CM_ "AUTOGENERATED FILE, DO NOT EDIT";

CM_ "fca_fastback_limited_edition_2024.dbc starts here";
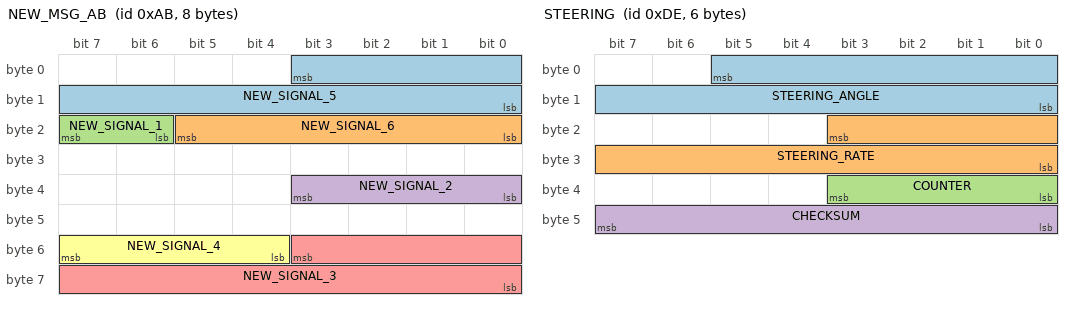
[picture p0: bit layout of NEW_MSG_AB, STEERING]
BO_ 171 NEW_MSG_AB: 8 XXX
 SG_ NEW_SIGNAL_5 : 3|12@0+ (1,0) [0|4095] "" XXX
 SG_ NEW_SIGNAL_6 : 21|6@0+ (1,0) [0|63] "" XXX
 SG_ NEW_SIGNAL_1 : 23|2@0+ (1,0) [0|3] "" XXX
 SG_ NEW_SIGNAL_2 : 35|4@0+ (1,0) [0|15] "" XXX
 SG_ NEW_SIGNAL_3 : 51|12@0+ (1,0) [0|4095] "" XXX
 SG_ NEW_SIGNAL_4 : 55|4@0+ (1,0) [0|15] "" XXX

BO_ 222 STEERING: 6 EPS
 SG_ STEERING_ANGLE : 5|14@0+ (0.1,-718.7) [0|16383] "deg" XXX
 SG_ STEERING_RATE : 19|12@0+ (0.5,-1000) [0|4095] "deg/s" XXX
 SG_ COUNTER : 35|4@0+ (1,0) [0|15] "" XXX
 SG_ CHECKSUM : 47|8@0+ (1,0) [0|255] "" XXX

BO_ 228 NEW_MSG_E4: 6 XXX
 SG_ NEW_SIGNAL_1 : 13|1@0+ (1,0) [0|1] "" XXX

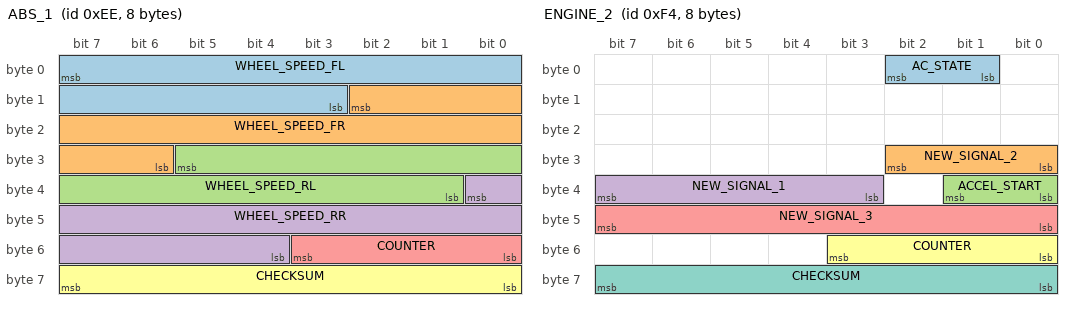
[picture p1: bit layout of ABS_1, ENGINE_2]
BO_ 238 ABS_1: 8 ABS
 SG_ WHEEL_SPEED_FL : 7|13@0+ (0.017,0) [0|8191] "m/s" XXX
 SG_ WHEEL_SPEED_FR : 10|13@0+ (0.017,0) [0|8191] "m/s" XXX
 SG_ WHEEL_SPEED_RL : 29|13@0+ (0.017,0) [0|8191] "m/s" XXX
 SG_ WHEEL_SPEED_RR : 32|13@0+ (0.017,0) [0|8191] "m/s" XXX
 SG_ COUNTER : 51|4@0+ (1,0) [0|15] "" XXX
 SG_ CHECKSUM : 63|8@0+ (1,0) [0|255] "" XXX

BO_ 241 NEW_MSG_F1: 8 XXX
 SG_ COUNTER : 51|4@0+ (1,0) [0|15] "" XXX
 SG_ CHECKSUM : 63|8@0+ (1,0) [0|255] "" XXX

BO_ 244 ENGINE_2: 8 XXX
 SG_ AC_STATE : 1|2@1+ (1,0) [0|7] "" XXX
 SG_ NEW_SIGNAL_2 : 24|3@1+ (1,0) [0|7] "" XXX
 SG_ ACCEL_START : 32|2@1+ (1,0) [0|3] "" XXX
 SG_ NEW_SIGNAL_1 : 35|5@1+ (1,0) [0|31] "" XXX
 SG_ NEW_SIGNAL_3 : 40|8@1+ (1,0) [0|255] "" XXX
 SG_ COUNTER : 51|4@0+ (1,0) [0|15] "" XXX
 SG_ CHECKSUM : 63|8@0+ (1,0) [0|255] "" XXX

BO_ 249 NEW_MSG_F9: 4 XXX
 SG_ COUNTER : 19|4@0+ (1,0) [0|15] "" XXX
 SG_ CHECKSUM : 31|8@0+ (1,0) [0|255] "" XXX

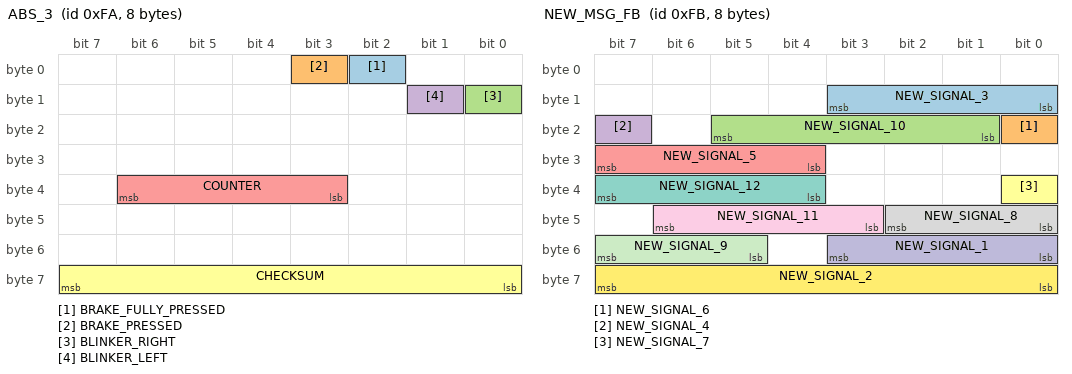
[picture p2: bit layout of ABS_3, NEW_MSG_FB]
BO_ 250 ABS_3: 8 ABS
 SG_ BRAKE_FULLY_PRESSED : 2|1@0+ (1,0) [0|1] "" XXX
 SG_ BRAKE_PRESSED : 3|1@0+ (1,0) [0|1] "" XXX
 SG_ BLINKER_RIGHT : 8|1@0+ (1,0) [0|1] "" XXX
 SG_ BLINKER_LEFT : 9|1@0+ (1,0) [0|1] "" XXX
 SG_ COUNTER : 38|4@0+ (1,0) [0|15] "" XXX
 SG_ CHECKSUM : 63|8@0+ (1,0) [0|255] "" XXX

BO_ 251 NEW_MSG_FB: 8 XXX
 SG_ NEW_SIGNAL_3 : 8|4@1+ (1,0) [0|15] "" XXX
 SG_ NEW_SIGNAL_6 : 16|1@0+ (1,0) [0|1] "" XXX
 SG_ NEW_SIGNAL_10 : 17|5@1+ (1,0) [0|31] "" XXX
 SG_ NEW_SIGNAL_4 : 23|1@0+ (1,0) [0|1] "" XXX
 SG_ NEW_SIGNAL_5 : 28|4@1+ (1,0) [0|15] "" XXX
 SG_ NEW_SIGNAL_7 : 32|1@0+ (1,0) [0|1] "" XXX
 SG_ NEW_SIGNAL_12 : 36|4@1+ (1,0) [0|15] "" XXX
 SG_ NEW_SIGNAL_8 : 40|3@1+ (1,0) [0|7] "" XXX
 SG_ NEW_SIGNAL_11 : 43|4@1+ (1,0) [0|15] "" XXX
 SG_ NEW_SIGNAL_1 : 48|4@1+ (1,0) [0|15] "" XXX
 SG_ NEW_SIGNAL_9 : 53|3@1+ (1,0) [0|7] "" XXX
 SG_ NEW_SIGNAL_2 : 56|8@1+ (1,0) [0|255] "" XXX

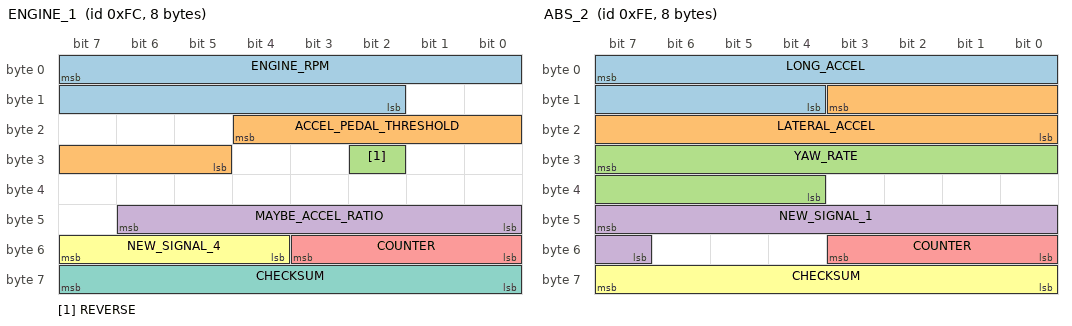
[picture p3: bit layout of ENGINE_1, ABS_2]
BO_ 252 ENGINE_1: 8 ENGINE
 SG_ ENGINE_RPM : 7|14@0+ (1,30) [0|255] "rev/min" XXX
 SG_ ACCEL_PEDAL_THRESHOLD : 20|8@0+ (0.3942,0) [0|255] "percent" XXX
 SG_ REVERSE : 26|1@0+ (1,0) [0|1] "" XXX
 SG_ MAYBE_ACCEL_RATIO : 40|7@1+ (1,0) [0|127] "" XXX
 SG_ COUNTER : 51|4@0+ (1,0) [0|15] "" XXX
 SG_ NEW_SIGNAL_4 : 52|4@1+ (1,0) [0|15] "" XXX
 SG_ CHECKSUM : 63|8@0+ (1,0) [0|255] "" XXX

BO_ 254 ABS_2: 8 ABS
 SG_ LONG_ACCEL : 7|12@0+ (0.01,-20.48) [0|4095] "m/s2" XXX
 SG_ LATERAL_ACCEL : 11|12@0+ (0.01,-20.48) [0|4095] "m/s2" XXX
 SG_ YAW_RATE : 31|12@0+ (-0.0014,2.86) [0|4095] "rad/s" XXX
 SG_ NEW_SIGNAL_1 : 47|9@0+ (1,0) [0|511] "" XXX
 SG_ COUNTER : 51|4@0+ (1,0) [0|15] "" XXX
 SG_ CHECKSUM : 63|8@0+ (1,0) [0|255] "" XXX

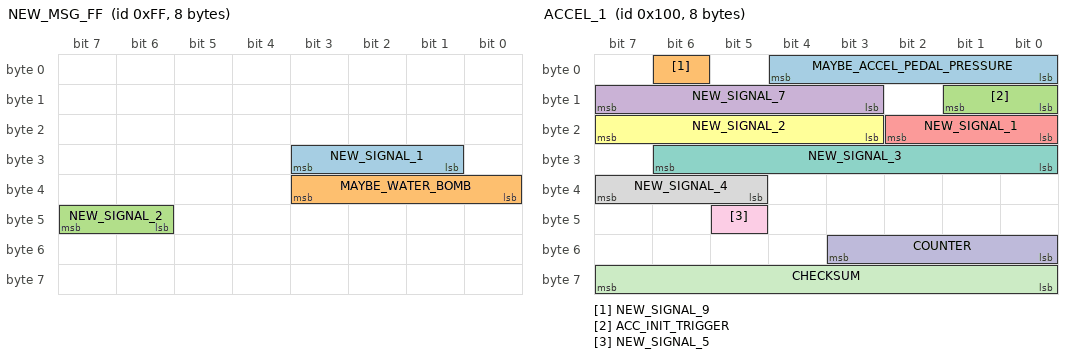
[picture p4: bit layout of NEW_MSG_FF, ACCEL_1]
BO_ 255 NEW_MSG_FF: 8 XXX
 SG_ NEW_SIGNAL_1 : 25|3@1+ (1,0) [0|7] "" XXX
 SG_ MAYBE_WATER_BOMB : 32|4@1+ (1,0) [0|15] "" XXX
 SG_ NEW_SIGNAL_2 : 46|2@1+ (1,0) [0|3] "" XXX

BO_ 256 ACCEL_1: 8 XXX
 SG_ MAYBE_ACCEL_PEDAL_PRESSURE : 0|5@1+ (1,0) [187|275] "%" XXX
 SG_ NEW_SIGNAL_9 : 6|1@0+ (1,0) [0|1] "" XXX
 SG_ ACC_INIT_TRIGGER : 8|2@1+ (1,0) [0|3] "" XXX
 SG_ NEW_SIGNAL_7 : 11|5@1+ (1,0) [0|31] "" XXX
 SG_ NEW_SIGNAL_1 : 16|3@1+ (1,0) [0|7] "" XXX
 SG_ NEW_SIGNAL_2 : 19|5@1+ (1,0) [0|3] "" XXX
 SG_ NEW_SIGNAL_3 : 24|7@1+ (1,0) [0|127] "" XXX
 SG_ NEW_SIGNAL_4 : 37|3@1+ (1,0) [0|7] "" XXX
 SG_ NEW_SIGNAL_5 : 45|1@0+ (1,0) [0|1] "" XXX
 SG_ COUNTER : 51|4@0+ (1,0) [0|15] "" XXX
 SG_ CHECKSUM : 63|8@0+ (1,0) [0|255] "" XXX

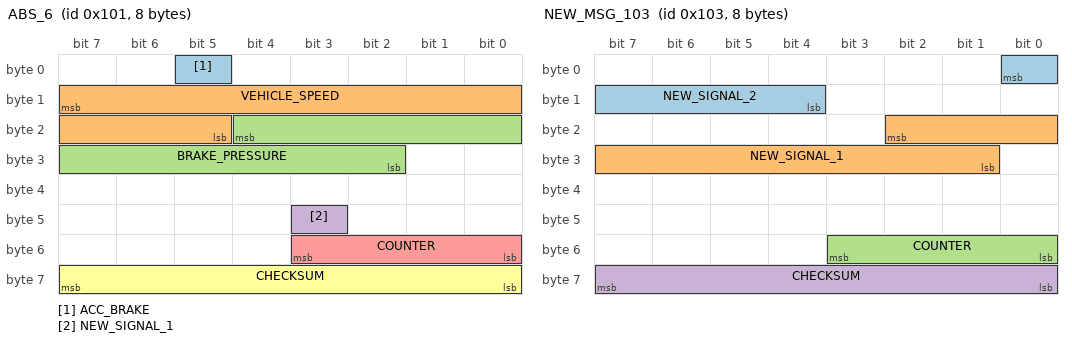
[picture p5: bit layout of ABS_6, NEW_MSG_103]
BO_ 257 ABS_6: 8 ABS
 SG_ ACC_BRAKE : 5|1@0+ (1,0) [0|1] "" XXX
 SG_ VEHICLE_SPEED : 15|11@0+ (0.062895,0) [0|2047] "km/h" XXX
 SG_ BRAKE_PRESSURE : 20|11@0+ (1,0) [0|2047] "" XXX
 SG_ NEW_SIGNAL_1 : 43|1@0+ (1,0) [0|1] "" XXX
 SG_ COUNTER : 51|4@0+ (1,0) [0|15] "" XXX
 SG_ CHECKSUM : 63|8@0+ (1,0) [0|255] "" XXX

BO_ 259 NEW_MSG_103: 8 XXX
 SG_ NEW_SIGNAL_2 : 0|5@0+ (1,0) [0|31] "" XXX
 SG_ NEW_SIGNAL_1 : 18|10@0+ (1,-500) [0|511] "" XXX
 SG_ COUNTER : 51|4@0+ (1,0) [0|15] "" XXX
 SG_ CHECKSUM : 63|8@0+ (1,0) [0|255] "" XXX

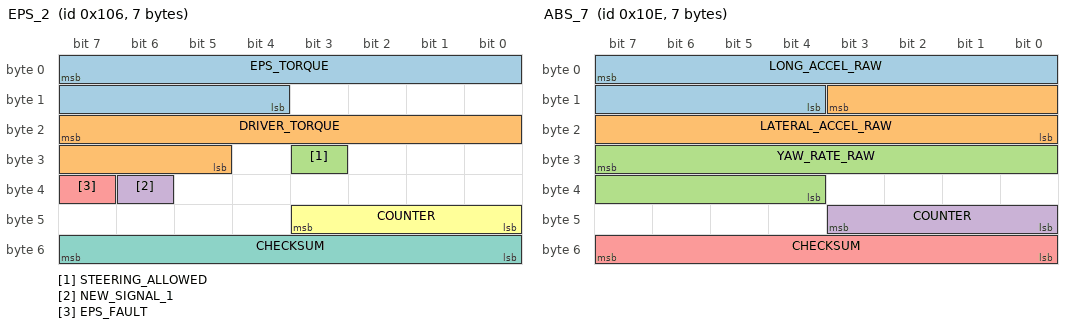
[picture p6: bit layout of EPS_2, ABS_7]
BO_ 262 EPS_2: 7 EPS
 SG_ EPS_TORQUE : 7|12@0+ (-1,2048) [0|4095] "" XXX
 SG_ DRIVER_TORQUE : 23|11@0+ (1,-1024) [0|2047] "" XXX
 SG_ STEERING_ALLOWED : 27|1@0+ (1,0) [0|1] "" XXX
 SG_ NEW_SIGNAL_1 : 38|1@0+ (1,0) [0|1] "" XXX
 SG_ EPS_FAULT : 39|1@0+ (1,0) [0|1] "" XXX
 SG_ COUNTER : 43|4@0+ (1,0) [0|15] "" XXX
 SG_ CHECKSUM : 55|8@0+ (1,0) [0|255] "" XXX

BO_ 265 NEW_MSG_109: 8 XXX
 SG_ COUNTER : 51|4@0+ (1,0) [0|15] "" XXX
 SG_ CHECKSUM : 63|8@0+ (1,0) [0|255] "" XXX

BO_ 270 ABS_7: 7 XXX
 SG_ LONG_ACCEL_RAW : 7|12@0+ (0.01,-20.48) [0|4095] "" XXX
 SG_ LATERAL_ACCEL_RAW : 11|12@0+ (0.01,-20.48) [0|4095] "" XXX
 SG_ YAW_RATE_RAW : 31|12@0+ (-0.0014,2.86) [0|4095] "" XXX
 SG_ COUNTER : 43|4@0+ (1,0) [0|15] "" XXX
 SG_ CHECKSUM : 55|8@0+ (1,0) [0|255] "" XXX

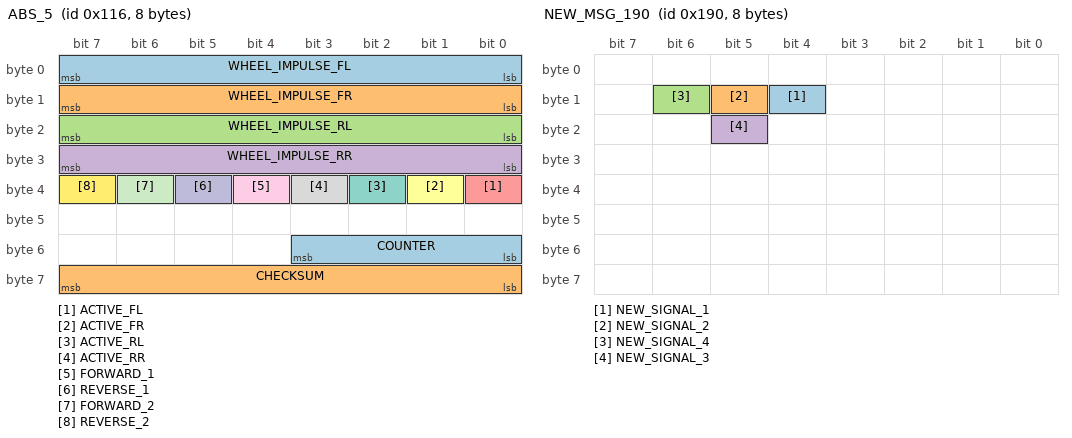
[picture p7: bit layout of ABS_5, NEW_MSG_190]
BO_ 278 ABS_5: 8 ABS
 SG_ WHEEL_IMPULSE_FL : 7|8@0+ (1,0) [0|255] "" XXX
 SG_ WHEEL_IMPULSE_FR : 15|8@0+ (1,0) [0|255] "" XXX
 SG_ WHEEL_IMPULSE_RL : 23|8@0+ (1,0) [0|255] "" XXX
 SG_ WHEEL_IMPULSE_RR : 31|8@0+ (1,0) [0|255] "" XXX
 SG_ ACTIVE_FL : 32|1@0+ (1,0) [0|1] "" XXX
 SG_ ACTIVE_FR : 33|1@0+ (1,0) [0|1] "" XXX
 SG_ ACTIVE_RL : 34|1@0+ (1,0) [0|1] "" XXX
 SG_ ACTIVE_RR : 35|1@0+ (1,0) [0|1] "" XXX
 SG_ FORWARD_1 : 36|1@0+ (1,0) [0|1] "" XXX
 SG_ REVERSE_1 : 37|1@0+ (1,0) [0|1] "" XXX
 SG_ FORWARD_2 : 38|1@0+ (1,0) [0|1] "" XXX
 SG_ REVERSE_2 : 39|1@0+ (1,0) [0|1] "" XXX
 SG_ COUNTER : 51|4@0+ (1,0) [0|15] "" XXX
 SG_ CHECKSUM : 63|8@0+ (1,0) [0|255] "" XXX

BO_ 280 NEW_MSG_118: 6 XXX
 SG_ COUNTER : 35|4@0+ (1,0) [0|15] "" XXX
 SG_ CHECKSUM : 47|8@0+ (1,0) [0|255] "" XXX

BO_ 282 NEW_MSG_11A: 8 XXX
 SG_ NEW_SIGNAL_1 : 7|11@0+ (1,-1000) [0|2047] "" XXX
 SG_ COUNTER : 51|4@0+ (1,0) [0|15] "" XXX
 SG_ CHECKSUM : 63|8@0+ (1,0) [0|255] "" XXX

BO_ 288 NEW_MSG_120: 6 XXX
 SG_ COUNTER : 19|4@0+ (1,0) [0|15] "" XXX
 SG_ CHECKSUM : 31|8@0+ (1,0) [0|255] "" XXX

BO_ 346 NEW_MSG_15A: 4 XXX
 SG_ MAYBE_COUNTER : 16|4@1+ (1,0) [0|15] "" XXX
 SG_ MAYBE_CHECKSUM : 24|8@1+ (1,0) [0|255] "" XXX

BO_ 400 NEW_MSG_190: 8 XXX
 SG_ NEW_SIGNAL_1 : 12|1@0+ (1,0) [0|1] "" XXX
 SG_ NEW_SIGNAL_2 : 13|1@0+ (1,0) [0|1] "" XXX
 SG_ NEW_SIGNAL_4 : 14|1@0+ (1,0) [0|1] "" XXX
 SG_ NEW_SIGNAL_3 : 21|1@0+ (1,0) [0|1] "" XXX

BO_ 496 NEW_MSG_1F0: 8 XXX
 SG_ NEW_SIGNAL_1 : 3|7@0+ (1,0) [0|63] "" XXX

BO_ 497 NEW_MSG_1F1: 8 XXX
 SG_ NEW_SIGNAL_1 : 0|3@1+ (1,0) [0|7] "" XXX

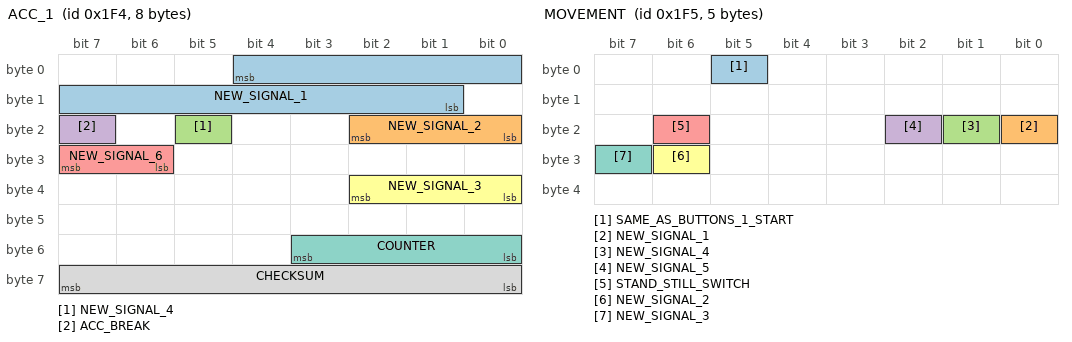
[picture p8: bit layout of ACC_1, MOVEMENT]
BO_ 500 ACC_1: 8 XXX
 SG_ NEW_SIGNAL_1 : 4|12@0+ (1,0) [0|31] "" XXX
 SG_ NEW_SIGNAL_2 : 16|3@1+ (1,0) [0|7] "" XXX
 SG_ NEW_SIGNAL_4 : 21|1@0+ (1,0) [0|1] "" XXX
 SG_ ACC_BREAK : 23|1@0+ (1,0) [0|1] "" XXX
 SG_ NEW_SIGNAL_6 : 30|2@1+ (1,0) [0|3] "" XXX
 SG_ NEW_SIGNAL_3 : 32|3@1+ (1,0) [0|7] "" XXX
 SG_ COUNTER : 51|4@0+ (1,0) [0|15] "" XXX
 SG_ CHECKSUM : 63|8@0+ (1,0) [0|255] "" XXX

BO_ 501 MOVEMENT: 5 XXX
 SG_ SAME_AS_BUTTONS_1_START : 5|1@0+ (1,0) [0|1] "" XXX
 SG_ NEW_SIGNAL_1 : 16|1@0+ (1,0) [0|1] "" XXX
 SG_ NEW_SIGNAL_4 : 17|1@0+ (1,0) [0|1] "" XXX
 SG_ NEW_SIGNAL_5 : 18|1@0+ (1,0) [0|1] "" XXX
 SG_ STAND_STILL_SWITCH : 22|1@0+ (1,0) [0|1] "" XXX
 SG_ NEW_SIGNAL_2 : 30|1@0+ (1,0) [0|1] "" XXX
 SG_ NEW_SIGNAL_3 : 31|1@0+ (1,0) [0|1] "" XXX

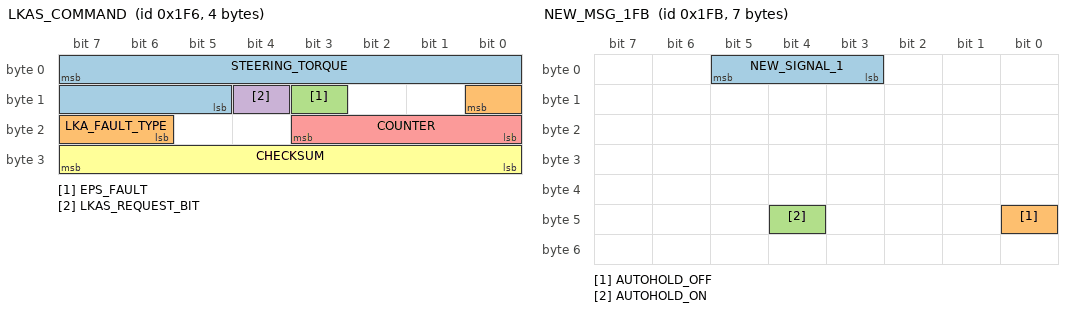
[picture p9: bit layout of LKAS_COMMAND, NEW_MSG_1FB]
BO_ 502 LKAS_COMMAND: 4 CAMERA
 SG_ STEERING_TORQUE : 7|11@0+ (1,-1024) [0|2047] "" XXX
 SG_ LKA_FAULT_TYPE : 8|3@0+ (1,0) [0|7] "" XXX
 SG_ EPS_FAULT : 11|1@0+ (1,0) [0|1] "" XXX
 SG_ LKAS_REQUEST_BIT : 12|1@0+ (1,0) [0|1] "" XXX
 SG_ COUNTER : 19|4@0+ (1,0) [0|1] "" XXX
 SG_ CHECKSUM : 31|8@0+ (1,0) [0|255] "" XXX

BO_ 503 NEW_MSG_1F7: 8 XXX
 SG_ NEW_SIGNAL_2 : 27|3@1+ (1,0) [0|7] "" XXX
 SG_ NEW_SIGNAL_1 : 32|1@0+ (1,0) [0|1] "" XXX

BO_ 507 NEW_MSG_1FB: 7 XXX
 SG_ NEW_SIGNAL_1 : 3|3@1+ (1,0) [0|7] "" XXX
 SG_ AUTOHOLD_OFF : 40|1@0+ (1,0) [0|1] "" XXX
 SG_ AUTOHOLD_ON : 44|1@0+ (1,0) [0|1] "" XXX

BO_ 508 NEW_MSG_1FC: 8 XXX
 SG_ NEW_SIGNAL_1 : 6|1@0+ (1,0) [0|1] "" XXX

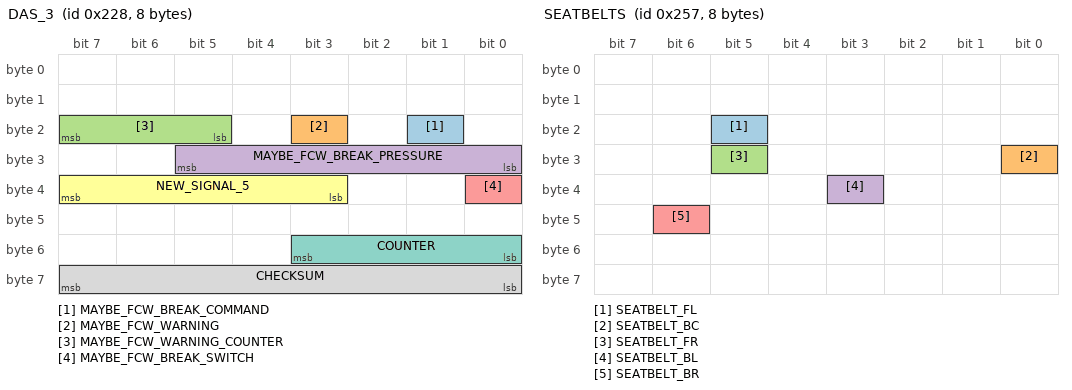
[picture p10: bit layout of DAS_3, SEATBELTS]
BO_ 552 DAS_3: 8 XXX
 SG_ MAYBE_FCW_BREAK_COMMAND : 17|1@0+ (1,0) [0|1] "" XXX
 SG_ MAYBE_FCW_WARNING : 19|1@0+ (1,0) [0|1] "" XXX
 SG_ MAYBE_FCW_WARNING_COUNTER : 21|3@1+ (1,0) [0|7] "" XXX
 SG_ MAYBE_FCW_BREAK_PRESSURE : 24|6@1+ (1,0) [0|63] "" XXX
 SG_ MAYBE_FCW_BREAK_SWITCH : 32|1@0+ (1,0) [0|1] "" XXX
 SG_ NEW_SIGNAL_5 : 35|5@1+ (1,0) [0|31] "" XXX
 SG_ COUNTER : 51|4@0+ (1,0) [0|15] "" XXX
 SG_ CHECKSUM : 63|8@0+ (1,0) [0|255] "" XXX

BO_ 592 NEW_MSG_250: 4 XXX
 SG_ NEW_SIGNAL_1 : 5|3@1+ (1,0) [0|7] "" XXX

BO_ 599 SEATBELTS: 8 XXX
 SG_ SEATBELT_FL : 21|1@0+ (1,0) [0|1] "" XXX
 SG_ SEATBELT_BC : 24|1@0+ (1,0) [0|1] "" XXX
 SG_ SEATBELT_FR : 29|1@0+ (1,0) [0|1] "" XXX
 SG_ SEATBELT_BL : 35|1@0+ (1,0) [0|1] "" XXX
 SG_ SEATBELT_BR : 46|1@0+ (1,0) [0|1] "" XXX

BO_ 601 NEW_MSG_259: 8 XXX
 SG_ NEW_SIGNAL_2 : 24|5@0+ (1,0) [0|31] "" XXX
 SG_ NEW_SIGNAL_1 : 47|8@0+ (1,0) [0|255] "" XXX

BO_ 748 SCM_1: 8 XXX
 SG_ WIPERS : 21|1@0+ (1,0) [0|1] "" XXX

BO_ 749 NEW_MSG_2ED: 8 XXX

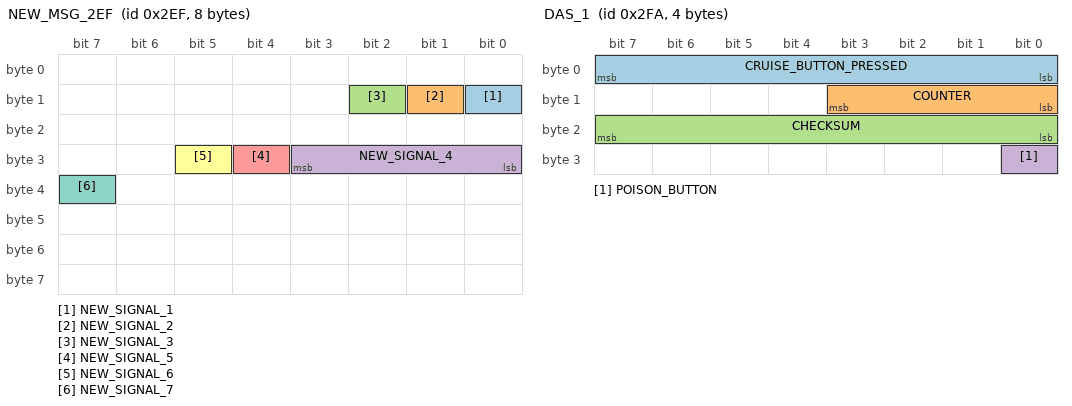
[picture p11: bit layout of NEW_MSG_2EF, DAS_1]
BO_ 751 NEW_MSG_2EF: 8 XXX
 SG_ NEW_SIGNAL_1 : 8|1@0+ (1,0) [0|1] "" XXX
 SG_ NEW_SIGNAL_2 : 9|1@0+ (1,0) [0|1] "" XXX
 SG_ NEW_SIGNAL_3 : 10|1@0+ (1,0) [0|1] "" XXX
 SG_ NEW_SIGNAL_4 : 24|4@1+ (1,0) [0|7] "" XXX
 SG_ NEW_SIGNAL_5 : 28|1@0+ (1,0) [0|1] "" XXX
 SG_ NEW_SIGNAL_6 : 29|1@0+ (1,0) [0|1] "" XXX
 SG_ NEW_SIGNAL_7 : 39|1@0+ (1,0) [0|1] "" XXX

BO_ 753 NEW_MSG_2F1: 8 XXX
 SG_ NEW_SIGNAL_2 : 16|3@1+ (1,0) [0|7] "" XXX
 SG_ NEW_SIGNAL_1 : 34|5@1+ (1,0) [0|31] "" XXX

BO_ 762 DAS_1: 4 XXX
 SG_ CRUISE_BUTTON_PRESSED : 7|8@0+ (1,0) [0|255] "" XXX
 SG_ COUNTER : 11|4@0+ (1,0) [0|15] "" XXX
 SG_ CHECKSUM : 23|8@0+ (1,0) [0|255] "" XXX
 SG_ POISON_BUTTON : 24|1@0+ (1,0) [0|1] "" XXX

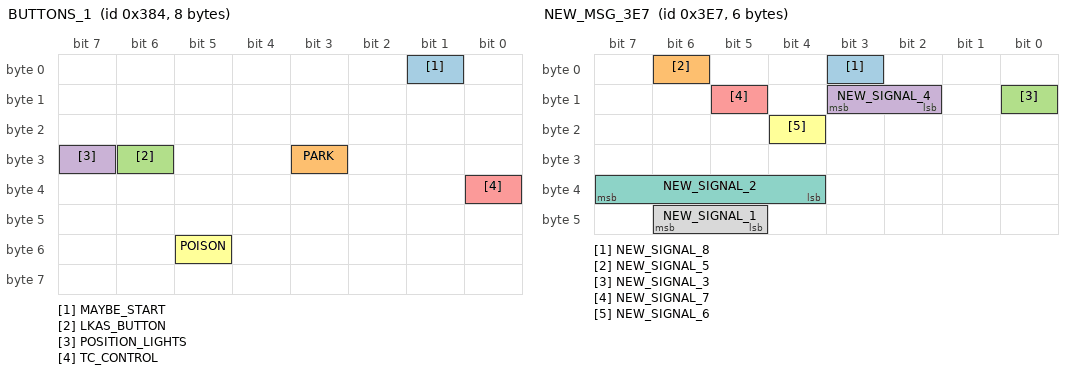
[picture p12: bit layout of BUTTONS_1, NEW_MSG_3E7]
BO_ 900 BUTTONS_1: 8 XXX
 SG_ MAYBE_START : 1|1@0+ (1,0) [0|1] "" XXX
 SG_ PARK : 27|1@0+ (1,0) [0|1] "" XXX
 SG_ LKAS_BUTTON : 30|1@1+ (1,0) [0|3] "" XXX
 SG_ POSITION_LIGHTS : 31|1@0+ (1,0) [0|1] "" XXX
 SG_ TC_CONTROL : 32|1@0+ (1,0) [0|1] "" XXX
 SG_ POISON : 53|1@0+ (1,0) [0|1] "" XXX

BO_ 999 NEW_MSG_3E7: 6 XXX
 SG_ NEW_SIGNAL_8 : 3|1@0+ (1,0) [0|1] "" XXX
 SG_ NEW_SIGNAL_5 : 6|1@0+ (1,0) [0|1] "" XXX
 SG_ NEW_SIGNAL_3 : 8|1@0+ (1,0) [0|1] "" XXX
 SG_ NEW_SIGNAL_4 : 10|2@1+ (1,0) [0|3] "" XXX
 SG_ NEW_SIGNAL_7 : 13|1@0+ (1,0) [0|1] "" XXX
 SG_ NEW_SIGNAL_6 : 20|1@0+ (1,0) [0|1] "" XXX
 SG_ NEW_SIGNAL_2 : 36|4@1+ (1,0) [0|15] "" XXX
 SG_ NEW_SIGNAL_1 : 45|2@1+ (1,0) [0|3] "" XXX

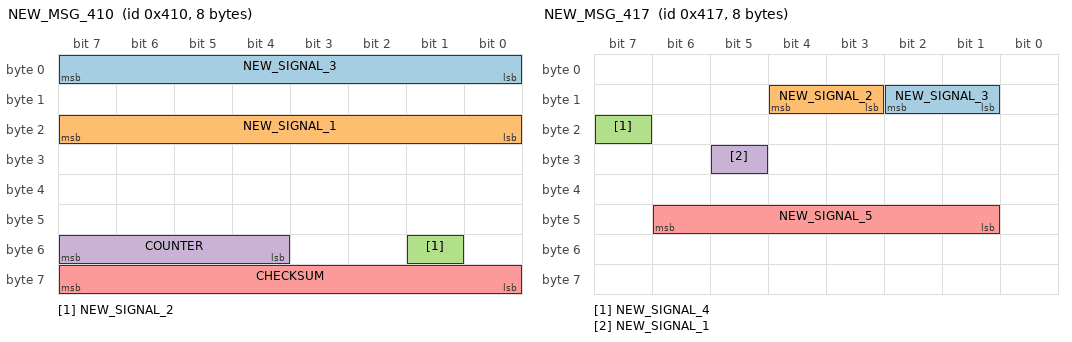
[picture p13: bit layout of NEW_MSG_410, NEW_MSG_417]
BO_ 1040 NEW_MSG_410: 8 XXX
 SG_ NEW_SIGNAL_3 : 7|8@0+ (1,0) [0|255] "" XXX
 SG_ NEW_SIGNAL_1 : 23|8@0+ (1,0) [0|255] "" XXX
 SG_ NEW_SIGNAL_2 : 49|1@0+ (1,0) [0|1] "" XXX
 SG_ COUNTER : 55|4@0+ (1,0) [0|15] "" XXX
 SG_ CHECKSUM : 63|8@0+ (1,0) [0|255] "" XXX

BO_ 1042 NEW_MSG_412: 5 XXX

BO_ 1046 NEW_MSG_416: 8 XXX
 SG_ MUX M : 1|2@0+ (1,0) [0|3] "" XXX
 SG_ UNKNOWN_M0_1 m0 : 15|8@0+ (1,0) [0|255] "" XXX
 SG_ UNKNOWN_M0_2 m0 : 23|8@0+ (1,0) [0|255] "" XXX
 SG_ UNKNOWN_M0_3 m0 : 31|8@0+ (1,0) [0|255] "" XXX
 SG_ UNKNOWN_M0_4 m0 : 39|8@0+ (1,0) [0|255] "" XXX
 SG_ UNKNOWN_M0_5 m0 : 47|8@0+ (1,0) [0|255] "" XXX
 SG_ UNKNOWN_M0_6 m0 : 55|8@0+ (1,0) [0|255] "" XXX
 SG_ UNKNOWN_M0_7 m0 : 63|8@0+ (1,0) [0|255] "" XXX
 SG_ UNKNOWN_M1_1 m1 : 15|8@0+ (1,0) [0|255] "" XXX
 SG_ UNKNOWN_M1_2 m1 : 23|8@0+ (1,0) [0|255] "" XXX
 SG_ UNKNOWN_M1_3 m1 : 31|8@0+ (1,0) [0|255] "" XXX
 SG_ UNKNOWN_M1_4 m1 : 39|8@0+ (1,0) [0|255] "" XXX
 SG_ UNKNOWN_M1_5 m1 : 47|8@0+ (1,0) [0|255] "" XXX
 SG_ UNKNOWN_M1_6 m1 : 55|8@0+ (1,0) [0|255] "" XXX
 SG_ UNKNOWN_M1_7 m1 : 63|8@0+ (1,0) [0|255] "" XXX
 SG_ UNKNOWN_M2_1 m2 : 15|8@0+ (1,0) [0|255] "" XXX
 SG_ UNKNOWN_M2_2 m2 : 23|8@0+ (1,0) [0|255] "" XXX
 SG_ UNKNOWN_M2_3 m2 : 31|8@0+ (1,0) [0|255] "" XXX
 SG_ UNKNOWN_M2_4 m2 : 39|8@0+ (1,0) [0|255] "" XXX
 SG_ UNKNOWN_M2_5 m2 : 47|8@0+ (1,0) [0|255] "" XXX
 SG_ UNKNOWN_M2_6 m2 : 55|8@0+ (1,0) [0|255] "" XXX
 SG_ UNKNOWN_M2_7 m2 : 63|8@0+ (1,0) [0|255] "" XXX

BO_ 1047 NEW_MSG_417: 8 XXX
 SG_ NEW_SIGNAL_3 : 10|2@0+ (1,0) [0|3] "" XXX
 SG_ NEW_SIGNAL_2 : 12|2@0+ (1,0) [0|3] "" XXX
 SG_ NEW_SIGNAL_4 : 23|1@0+ (1,0) [0|1] "" XXX
 SG_ NEW_SIGNAL_1 : 29|1@0+ (1,0) [0|1] "" XXX
 SG_ NEW_SIGNAL_5 : 41|6@1+ (1,0) [0|63] "" XXX

BO_ 1048 NEW_MSG_418: 4 XXX
 SG_ COUNTER : 19|4@0+ (1,0) [0|15] "" XXX
 SG_ CHECKSUM : 31|8@0+ (1,0) [0|255] "" XXX

BO_ 1049 NEW_MSG_419: 8 XXX
 SG_ NEW_SIGNAL_1 : 5|6@0+ (1,0) [0|1] "" XXX
 SG_ SOMETHING_TO_DO_WITH_DR_DOOR : 21|3@1+ (1,0) [0|3] "" XXX
 SG_ NEW_SIGNAL_4 : 26|2@1+ (1,0) [0|3] "" XXX

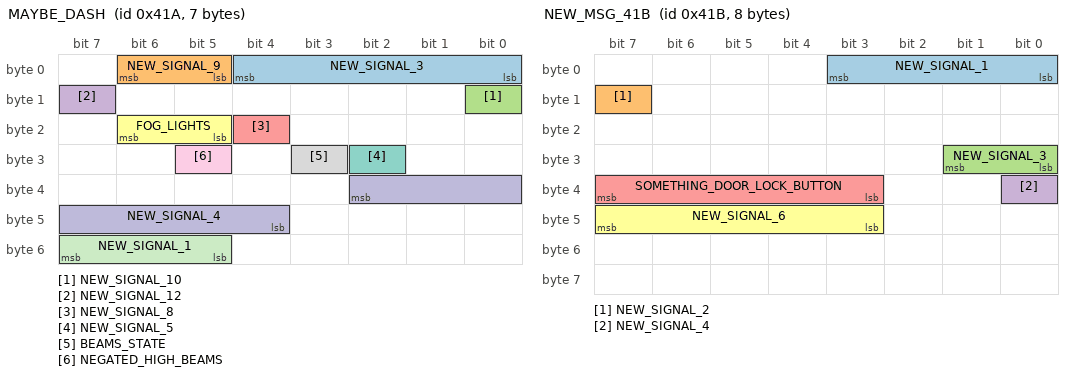
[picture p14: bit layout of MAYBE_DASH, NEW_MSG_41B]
BO_ 1050 MAYBE_DASH: 7 XXX
 SG_ NEW_SIGNAL_3 : 0|5@1+ (1,0) [0|31] "" XXX
 SG_ NEW_SIGNAL_9 : 5|2@1+ (1,0) [0|3] "" XXX
 SG_ NEW_SIGNAL_10 : 8|1@0+ (1,0) [0|1] "" XXX
 SG_ NEW_SIGNAL_12 : 15|1@0+ (1,0) [0|1] "" XXX
 SG_ NEW_SIGNAL_8 : 20|1@0+ (1,0) [0|1] "" XXX
 SG_ FOG_LIGHTS : 21|2@1+ (1,0) [0|3] "" XXX
 SG_ NEW_SIGNAL_5 : 26|1@0+ (1,0) [0|1] "" XXX
 SG_ BEAMS_STATE : 27|1@0+ (1,0) [0|1] "" XXX
 SG_ NEGATED_HIGH_BEAMS : 29|1@0+ (1,0) [0|1] "" XXX
 SG_ NEW_SIGNAL_4 : 34|7@0+ (1,0) [0|63] "" XXX
 SG_ NEW_SIGNAL_1 : 53|3@1+ (1,0) [0|7] "" XXX

BO_ 1051 NEW_MSG_41B: 8 XXX
 SG_ NEW_SIGNAL_1 : 0|4@1+ (1,0) [0|15] "" XXX
 SG_ NEW_SIGNAL_2 : 15|1@0+ (1,0) [0|1] "" XXX
 SG_ NEW_SIGNAL_3 : 25|2@0+ (1,0) [0|1] "" XXX
 SG_ NEW_SIGNAL_4 : 32|1@0+ (1,0) [0|1] "" XXX
 SG_ SOMETHING_DOOR_LOCK_BUTTON : 35|5@1+ (1,0) [0|31] "" XXX
 SG_ NEW_SIGNAL_6 : 43|5@1+ (1,0) [0|31] "" XXX

BO_ 1053 NEW_MSG_41D: 8 XXX
 SG_ NEW_SIGNAL_1 : 16|7@1+ (1,0) [0|127] "" XXX

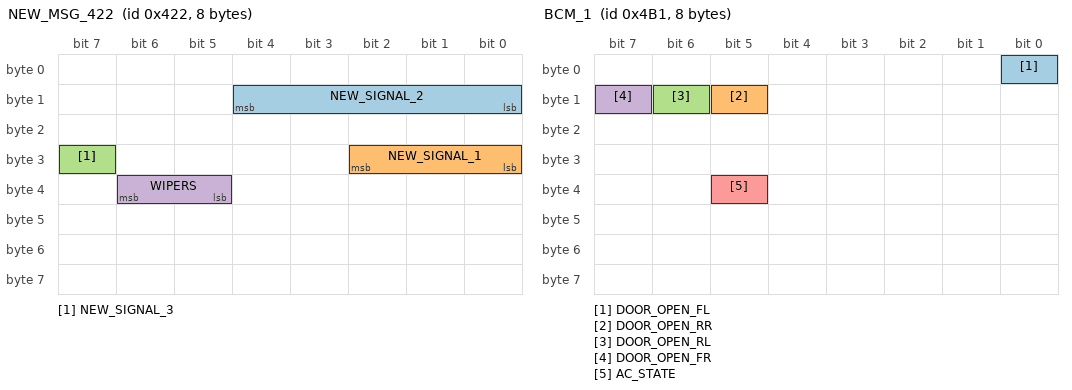
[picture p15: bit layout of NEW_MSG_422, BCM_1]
BO_ 1058 NEW_MSG_422: 8 XXX
 SG_ NEW_SIGNAL_2 : 8|5@1+ (1,0) [0|31] "" XXX
 SG_ NEW_SIGNAL_1 : 24|3@1+ (1,0) [0|7] "" XXX
 SG_ NEW_SIGNAL_3 : 31|1@0+ (1,0) [0|1] "" XXX
 SG_ WIPERS : 37|2@1+ (1,0) [0|3] "" XXX

BO_ 1062 NEW_MSG_426: 8 XXX

BO_ 1199 NEW_MSG_4AF: 8 XXX
 SG_ NEW_SIGNAL_1 : 2|1@0+ (1,0) [0|1] "" XXX
 SG_ NEW_SIGNAL_2 : 15|1@0+ (1,0) [0|1] "" XXX

BO_ 1201 BCM_1: 8 XXX
 SG_ DOOR_OPEN_FL : 0|1@0+ (1,0) [0|1] "" XXX
 SG_ DOOR_OPEN_RR : 13|1@0+ (1,0) [0|1] "" XXX
 SG_ DOOR_OPEN_RL : 14|1@0+ (1,0) [0|1] "" XXX
 SG_ DOOR_OPEN_FR : 15|1@0+ (1,0) [0|1] "" XXX
 SG_ AC_STATE : 37|1@0+ (1,0) [0|1] "" XXX

BO_ 1202 NEW_MSG_4B2: 8 XXX
 SG_ NEW_SIGNAL_1 : 16|1@0+ (1,0) [0|1] "" XXX
 SG_ NEW_SIGNAL_2 : 30|2@1+ (1,0) [0|3] "" XXX

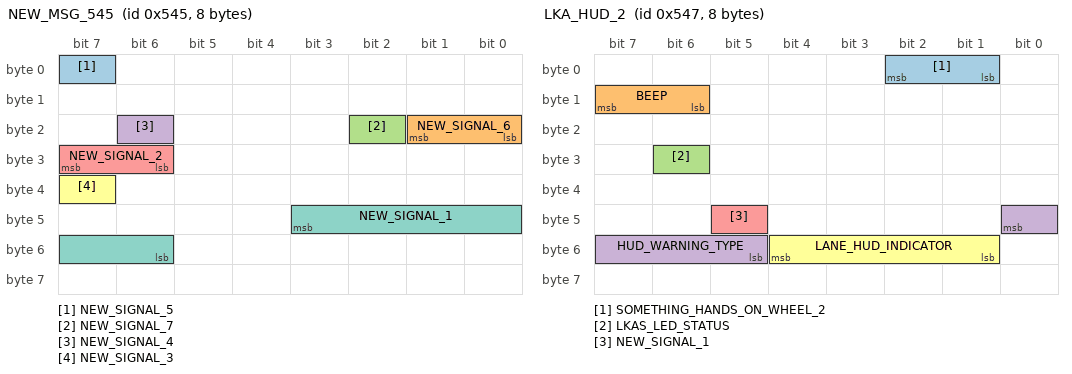
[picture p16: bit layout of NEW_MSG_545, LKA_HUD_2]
BO_ 1349 NEW_MSG_545: 8 XXX
 SG_ NEW_SIGNAL_5 : 7|1@0+ (1,0) [0|1] "" XXX
 SG_ NEW_SIGNAL_6 : 17|2@0+ (1,0) [0|1] "" XXX
 SG_ NEW_SIGNAL_7 : 18|1@0+ (1,0) [0|1] "" XXX
 SG_ NEW_SIGNAL_4 : 22|1@0+ (1,0) [0|1] "" XXX
 SG_ NEW_SIGNAL_2 : 30|2@1+ (1,0) [0|3] "" XXX
 SG_ NEW_SIGNAL_3 : 39|1@0+ (1,0) [0|1] "" XXX
 SG_ NEW_SIGNAL_1 : 43|6@0+ (1,0) [0|7] "" XXX

BO_ 1351 LKA_HUD_2: 8 CAMERA
 SG_ SOMETHING_HANDS_ON_WHEEL_2 : 1|2@1+ (1,0) [0|3] "" XXX
 SG_ BEEP : 14|2@1+ (1,0) [0|3] "" XXX
 SG_ LKAS_LED_STATUS : 30|1@0+ (1,0) [0|1] "" XXX
 SG_ HUD_WARNING_TYPE : 40|4@0+ (1,0) [0|1] "" XXX
 SG_ NEW_SIGNAL_1 : 45|1@0+ (1,0) [0|1] "" XXX
 SG_ LANE_HUD_INDICATOR : 52|4@0+ (1,0) [0|7] "" XXX

BO_ 1354 NEW_MSG_54A: 8 XXX
 SG_ NEW_SIGNAL_1 : 8|2@1+ (1,0) [0|3] "" XXX
 SG_ NEW_SIGNAL_2 : 20|4@1+ (1,0) [0|15] "" XXX
 SG_ NEW_SIGNAL_3 : 30|1@0+ (1,0) [0|1] "" XXX

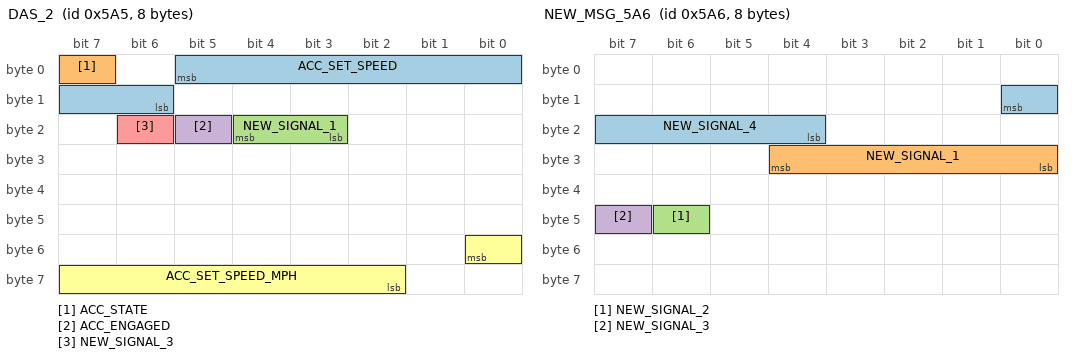
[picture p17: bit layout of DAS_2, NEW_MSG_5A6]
BO_ 1445 DAS_2: 8 XXX
 SG_ ACC_SET_SPEED : 5|8@0+ (1,0) [0|255] "km/h" XXX
 SG_ ACC_STATE : 7|1@0+ (1,0) [0|1] "" XXX
 SG_ NEW_SIGNAL_1 : 19|2@1+ (1,0) [0|3] "" XXX
 SG_ ACC_ENGAGED : 21|1@0+ (1,0) [0|1] "" XXX
 SG_ NEW_SIGNAL_3 : 22|1@0+ (1,0) [0|1] "" XXX
 SG_ ACC_SET_SPEED_MPH : 48|7@0+ (1,0) [0|127] "mph" XXX

BO_ 1446 NEW_MSG_5A6: 8 XXX
 SG_ NEW_SIGNAL_4 : 8|5@0+ (1,0) [0|31] "" XXX
 SG_ NEW_SIGNAL_1 : 24|5@1+ (1,0) [0|31] "" XXX
 SG_ NEW_SIGNAL_2 : 46|1@0+ (1,0) [0|1] "" XXX
 SG_ NEW_SIGNAL_3 : 47|1@0+ (1,0) [0|1] "" XXX

BO_ 1447 NEW_MSG_5A7: 8 XXX
 SG_ NEW_SIGNAL_1 : 5|1@0+ (1,0) [0|1] "" XXX

BO_ 1448 GEAR: 8 XXX
 SG_ PARK : 4|1@0+ (1,0) [0|1] "" XXX
 SG_ P_OR_N : 7|1@0+ (1,0) [0|1] "" XXX
 SG_ MANUAL_SHIFT_MINUS : 8|1@0+ (1,0) [0|1] "" XXX
 SG_ NEW_SIGNAL_1 : 9|1@0+ (1,0) [0|1] "" XXX
 SG_ BEEP : 11|2@0+ (1,0) [0|3] "" XXX
 SG_ NEW_SIGNAL_5 : 13|1@0+ (1,0) [0|1] "" XXX
 SG_ DRIVE : 16|1@0+ (1,0) [0|1] "" XXX
 SG_ BREAK_PRESSED_ON_N : 18|1@0+ (1,0) [0|1] "" XXX
 SG_ GEAR_SHIFT : 19|1@0+ (1,0) [0|1] "" XXX
 SG_ MANUAL_SHIFT_PLUS_OR_PARK : 21|1@0+ (1,0) [0|7] "" XXX
 SG_ MANUAL_GEAR : 22|1@0+ (1,0) [0|1] "" XXX
 SG_ D_2 : 23|1@0+ (1,0) [0|1] "" XXX
 SG_ MAYBE_GEAR_NUMBER : 24|1@0+ (1,0) [0|1] "" XXX
 SG_ REVERSE : 25|2@1+ (1,0) [0|7] "" XXX
 SG_ MAYBE_AUTO_SHIFT : 28|1@0+ (1,0) [0|1] "" XXX
 SG_ NEW_SIGNAL_8 : 29|1@0+ (1,0) [0|1] "" XXX
 SG_ P_OR_D : 30|1@0+ (1,0) [0|1] "" XXX
 SG_ NEUTRAL : 31|1@0+ (1,0) [0|1] "" XXX
 SG_ P_OR_R : 32|3@1+ (1,0) [0|7] "" XXX
 SG_ MAYBE_D1_D_OR_PARK : 39|1@0+ (1,0) [0|1] "" XXX
 SG_ NEW_SIGNAL_2 : 47|2@0+ (1,0) [0|1] "" XXX
 SG_ COUNTER : 51|4@0+ (1,0) [0|15] "" XXX
 SG_ CHECKSUM : 63|8@0+ (1,0) [0|255] "" XXX

BO_ 1449 NEW_MSG_5A9: 8 XXX
 SG_ NEW_SIGNAL_2 : 12|1@0+ (1,0) [0|1] "" XXX
 SG_ NEW_SIGNAL_1 : 21|3@1+ (1,0) [0|7] "" XXX

BO_ 1454 NEW_MSG_5AE: 8 XXX

BO_ 1456 BUTTONS_3: 8 XXX
 SG_ PARKING_ASSIST_BUTTON : 13|1@0+ (1,0) [0|1] "" XXX

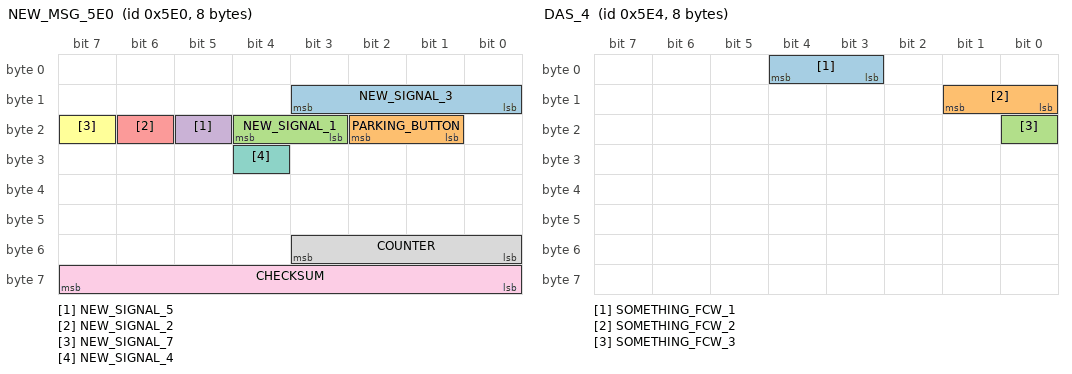
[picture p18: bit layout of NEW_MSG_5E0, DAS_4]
BO_ 1504 NEW_MSG_5E0: 8 XXX
 SG_ NEW_SIGNAL_3 : 8|4@1+ (1,0) [0|15] "" XXX
 SG_ PARKING_BUTTON : 17|2@1+ (1,0) [0|3] "" XXX
 SG_ NEW_SIGNAL_1 : 19|2@1+ (1,0) [0|3] "" XXX
 SG_ NEW_SIGNAL_5 : 21|1@0+ (1,0) [0|1] "" XXX
 SG_ NEW_SIGNAL_2 : 22|1@0+ (1,0) [0|1] "" XXX
 SG_ NEW_SIGNAL_7 : 23|1@0+ (1,0) [0|1] "" XXX
 SG_ NEW_SIGNAL_4 : 28|1@0+ (1,0) [0|1] "" XXX
 SG_ COUNTER : 51|4@0+ (1,0) [0|15] "" XXX
 SG_ CHECKSUM : 63|8@0+ (1,0) [0|255] "" XXX

BO_ 1508 DAS_4: 8 XXX
 SG_ SOMETHING_FCW_1 : 4|2@0+ (1,0) [0|3] "" XXX
 SG_ SOMETHING_FCW_2 : 9|2@0+ (1,0) [0|3] "" XXX
 SG_ SOMETHING_FCW_3 : 16|1@0+ (1,0) [0|1] "" XXX

BO_ 1538 BUTTONS_2: 8 XXX
 SG_ POISON_STATE : 7|1@0+ (1,0) [0|1] "" XXX

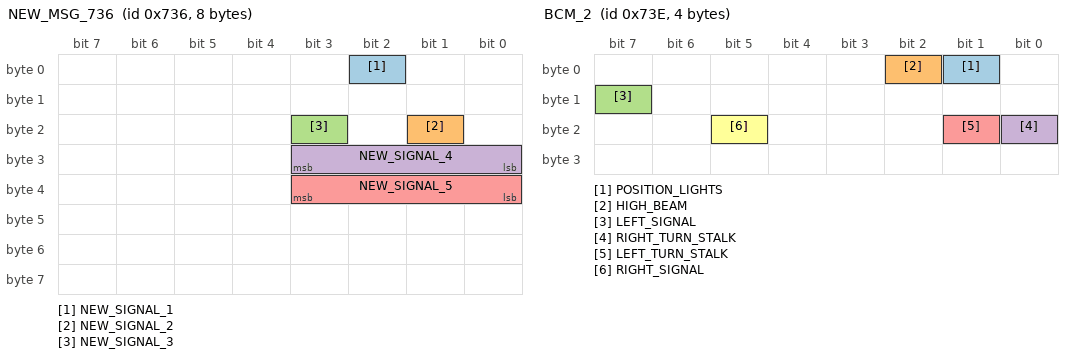
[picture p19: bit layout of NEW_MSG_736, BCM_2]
BO_ 1846 NEW_MSG_736: 8 XXX
 SG_ NEW_SIGNAL_1 : 2|1@0+ (1,0) [0|1] "" XXX
 SG_ NEW_SIGNAL_2 : 17|1@0+ (1,0) [0|1] "" XXX
 SG_ NEW_SIGNAL_3 : 19|1@0+ (1,0) [0|1] "" XXX
 SG_ NEW_SIGNAL_4 : 24|4@1+ (1,0) [0|15] "" XXX
 SG_ NEW_SIGNAL_5 : 32|4@1+ (1,0) [0|15] "" XXX

BO_ 1848 NEW_MSG_738: 5 XXX
 SG_ NEW_SIGNAL_1 : 9|1@0+ (1,0) [0|1] "" XXX
 SG_ WARNING_KEY_NOT_PRESENT : 13|1@0+ (1,0) [0|1] "" XXX

BO_ 1850 NEW_MSG_73A: 6 XXX
 SG_ NEW_SIGNAL_1 : 8|1@0+ (1,0) [0|1] "" XXX

BO_ 1854 BCM_2: 4 BCM
 SG_ POSITION_LIGHTS : 1|1@0+ (1,0) [0|1] "" XXX
 SG_ HIGH_BEAM : 2|1@0+ (1,0) [0|1] "" XXX
 SG_ LEFT_SIGNAL : 15|1@0+ (1,0) [0|1] "" XXX
 SG_ RIGHT_TURN_STALK : 16|1@0+ (1,0) [0|1] "" XXX
 SG_ LEFT_TURN_STALK : 17|1@0+ (1,0) [0|1] "" XXX
 SG_ RIGHT_SIGNAL : 21|1@0+ (1,0) [0|1] "" XXX

BO_ 1865 NEW_MSG_749: 8 XXX
 SG_ NEW_SIGNAL_1 : 23|2@0+ (1,0) [0|3] "" XXX

BO_ 417001768 NEW_MSG_18DAF128: 8 XXX

BO_ 417001776 NEW_MSG_18DAF130: 4 XXX

BO_ 417002024 NEW_MSG_18DAF228: 8 XXX

BO_ 506724352 NEW_MSG_1E340000: 8 XXX
 SG_ NEW_SIGNAL_3 : 8|1@0+ (1,0) [0|1] "" XXX
 SG_ NEW_SIGNAL_2 : 9|1@0+ (1,0) [0|1] "" XXX

BO_ 506724417 NEW_MSG_1E340041: 4 XXX

BO_ 506855454 NEW_MSG_1E36001E: 1 XXX
 SG_ NEW_SIGNAL_1 : 1|1@0+ (1,0) [0|1] "" XXX

CM_ SG_ 254 LONG_ACCEL "scale TBD";
CM_ SG_ 254 LATERAL_ACCEL "scale TBD";
CM_ SG_ 254 YAW_RATE "scale estimated";
CM_ SG_ 257 ACC_BRAKE "may correlate with ACC-actuated braking";
CM_ SG_ 262 STEERING_ALLOWED "Steering is only allowed to start above 10kph and remain above 5pkh";
CM_ SG_ 278 FORWARD_1 "probably per-axle";
CM_ SG_ 278 REVERSE_1 "probably per-axle";
CM_ SG_ 278 FORWARD_2 "probably per-axle";
CM_ SG_ 278 REVERSE_2 "probably per-axle";
CM_ SG_ 282 NEW_SIGNAL_1 "smoothed yaw rate with low speed cutoff, maybe active forward lighting target angle";
CM_ SG_ 502 COUNTER "correlates with steering wheel haptic";
CM_ SG_ 1448 BREAK_PRESSED_ON_N "Shows when on N without break pressed";
VAL_ 244 AC_STATE 1 "OFF" 2 "ON";
VAL_ 244 ACCEL_START 1 "NOT_TRIGGERED" 2 "TRIGGERED";
VAL_ 250 BRAKE_FULLY_PRESSED 0 "NO" 1 "YES";
VAL_ 250 BRAKE_PRESSED 1 "PRESSED" 0 "NOT_PRESSED";
VAL_ 250 BLINKER_RIGHT 0 "OFF" 1 "ON";
VAL_ 250 BLINKER_LEFT 0 "OFF" 1 "ON";
VAL_ 262 STEERING_ALLOWED 0 "YES" 1 "NO";
VAL_ 262 EPS_FAULT 0 "NO" 1 "YES";
VAL_ 501 STAND_STILL_SWITCH 0 "STILL" 1 "MOVING";
VAL_ 502 LKA_FAULT_TYPE 0 "OFF" 7 "EPS";
VAL_ 502 EPS_FAULT 0 "NO" 1 "YES";
VAL_ 502 LKAS_REQUEST_BIT 0 "OFF" 1 "ON";
VAL_ 599 SEATBELT_FL 1 "UNLATCHED" 0 "LATCHED";
VAL_ 599 SEATBELT_BC 0 "UNLATCHED" 1 "LATCHED";
VAL_ 599 SEATBELT_FR 0 "LATCHED";
VAL_ 599 SEATBELT_BL 0 "LATCHED" 1 "UNLATCHED";
VAL_ 599 SEATBELT_BR 0 "LATCHED" 1 "UNLATCHED";
VAL_ 762 CRUISE_BUTTON_PRESSED 0 "NOT_PRESSED" 8 "ACC_RESUME" 16 "ACC_DECREASE" 32 "ACC_INCREASE" 128 "ACC_CANCEL" 2 "ACC_START";
VAL_ 762 POISON_BUTTON 0 "NOT_PRESSED" 1 "PRESSED";
VAL_ 900 LKAS_BUTTON 0 "NOT_PRESSED" 1 "PRESSED";
VAL_ 900 POSITION_LIGHTS 0 "OFF" 1 "ON";
VAL_ 900 TC_CONTROL 0 "NOT_PRESSED" 1 "PRESSED";
VAL_ 1050 FOG_LIGHTS 0 "OFF" 3 "ON";
VAL_ 1050 BEAMS_STATE 0 "OFF" 1 "ON";
VAL_ 1201 AC_STATE 0 "OFF" 1 "ON";
VAL_ 1351 BEEP 0 "OFF" 1 "RIGHT_ON" 2 "LEFT_ON" 3 "BOTH_ON";
VAL_ 1351 LKAS_LED_STATUS 0 "OFF" 1 "ON";
VAL_ 1351 HUD_WARNING_TYPE 15 "LKA_UNAVAILABLE_WARNING" 6 "HANDS_ON_WHEEL_WARNING";
VAL_ 1351 LANE_HUD_INDICATOR 0 "HIDDEN" 1 "IDLE" 2 "LEFT_ON_CENTERED" 8 "LEFT_LANE_ON" 6 "LANE_CENTERED" 10 "ALIGNED_RIGHT" 3 "RIGHT_ON_CENTERED" 4 "HUGGING_LEFT" 5 "HUGGING_RIGHT" 7 "ALIGNED_LEFT" 9 "RIGHT_LANE_ON" 1 "LEFT_LANE_BLINKING" 12 "RIGHT_LANE_BLINKING" 11 "LEFT_LANE_BLINKING" 14 "LEFT_LANE_ON" 15 "RIGHT_LANE_ON" 13 "RIGHT_LANE_BLINKING";
VAL_ 1445 ACC_STATE 0 "OFF" 1 "READY";
VAL_ 1445 ACC_ENGAGED 0 "NOT_ENGAGED" 1 "ENGAGED";
VAL_ 1448 BEEP 0 "SILENT" 2 "BEEPING";
VAL_ 1448 BREAK_PRESSED_ON_N 0 "PRESSED" 1 "NOT_PRESSED";
VAL_ 1448 GEAR_SHIFT 0 "IDLE" 1 "SHIFTING";
VAL_ 1448 P_OR_R 0 "NONE" 6 "PARK";
VAL_ 1456 PARKING_ASSIST_BUTTON 0 "NOT_PRESSED" 1 "PRESSED";
VAL_ 1504 PARKING_BUTTON 0 "NOT_PRESSED" 1 "PUSHED_DOWN" 2 "PULLED_UP";
VAL_ 1538 POISON_STATE 0 "DEACTIVATED" 1 "ACTIVATED";
VAL_ 1848 WARNING_KEY_NOT_PRESENT 0 "NOT_SHOWN" 1 "SHOWN";
VAL_ 1854 POSITION_LIGHTS 0 "OFF" 1 "ON";
VAL_ 1854 HIGH_BEAM 0 "OFF" 1 "ON";
